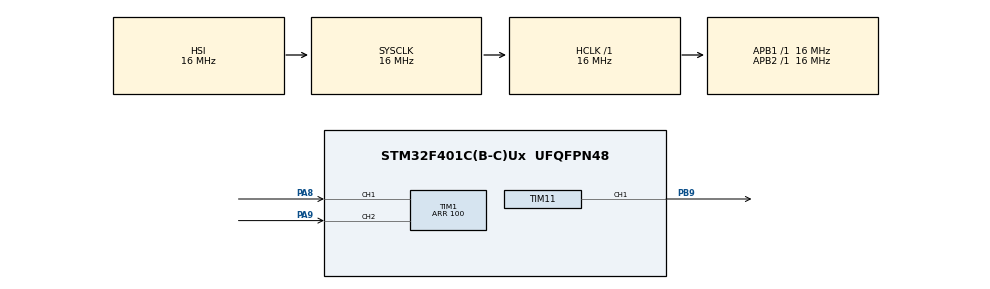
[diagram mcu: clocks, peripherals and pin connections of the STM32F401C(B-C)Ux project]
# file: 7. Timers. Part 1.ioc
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Mcu.Family=STM32F4
Mcu.Name=STM32F401C(B-C)Ux
Mcu.Package=UFQFPN48
NVIC.PriorityGroup=NVIC_PRIORITYGROUP_4
PA13.Mode=Serial_Wire
PA13.Signal=SYS_JTMS-SWDIO
PA14.Mode=Serial_Wire
PA14.Signal=SYS_JTCK-SWCLK
PA8.Signal=S_TIM1_CH1
PA9.Signal=S_TIM1_CH2
PB9.Signal=S_TIM11_CH1
ProjectManager.HeapSize=0x200
ProjectManager.StackSize=0x400
ProjectManager.TargetToolchain=STM32CubeIDE
RCC.AHBFreq_Value=16000000
RCC.APB1Freq_Value=16000000
RCC.APB2Freq_Value=16000000
RCC.CortexFreq_Value=16000000
RCC.HSE_VALUE=25000000
RCC.HSI_VALUE=16000000
RCC.LSE_VALUE=32768
RCC.SYSCLKFreq_VALUE=16000000
RCC.VCOOutputFreq_Value=192000000
SH.S_TIM11_CH1.0=TIM11_CH1,PWM Generation1 CH1
SH.S_TIM1_CH1.0=TIM1_CH1,Encoder_Interface
SH.S_TIM1_CH2.0=TIM1_CH2,Encoder_Interface
TIM1.EncoderMode=TIM_ENCODERMODE_TI12
TIM1.Period=100
TIM11.Channel=TIM_CHANNEL_1
TIM11.OCPolarity_1=TIM_OCPOLARITY_LOW
TIM11.Period=100-1
TIM11.Prescaler=16
VP_TIM11_VS_ClockSourceINT.Mode=Enable_Timer
board=custom

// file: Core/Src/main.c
/* USER CODE BEGIN Header */
/**
  ******************************************************************************
  * @file           : main.c
  * @brief          : Main program body
  ******************************************************************************
  * @attention
  *
  * Copyright (c) 2024 STMicroelectronics.
  * All rights reserved.
  *
  * This software is licensed under terms that can be found in the LICENSE file
  * in the root directory of this software component.
  * If no LICENSE file comes with this software, it is provided AS-IS.
  *
  ******************************************************************************
  */
/* USER CODE END Header */
#include "main.h"
#include "tim.h"
#include "gpio.h"

void SystemClock_Config(void);

int main(void)
{

  /* MCU Configuration--------------------------------------------------------*/

  /* Reset of all peripherals, Initializes the Flash interface and the Systick. */
  HAL_Init();

  /* Configure the system clock */
  SystemClock_Config();

  /* Initialize all configured peripherals */
  MX_GPIO_Init();
  MX_TIM1_Init();
  MX_TIM11_Init();

  /* Infinite loop */
  /* USER CODE BEGIN WHILE */

  TIM1_Encoder_Start();
  TIM11_PWM_Start();

  while (1)
  {
	TIM11->CCR1 = TIM1->CNT;
    /* USER CODE END WHILE */

    /* USER CODE BEGIN 3 */
  }

  return 0;
  /* USER CODE END 3 */
}

void SystemClock_Config(void)
{
  RCC_OscInitTypeDef RCC_OscInitStruct = {0};
  RCC_ClkInitTypeDef RCC_ClkInitStruct = {0};

  /** Configure the main internal regulator output voltage
  */
  __HAL_RCC_PWR_CLK_ENABLE();
  __HAL_PWR_VOLTAGESCALING_CONFIG(PWR_REGULATOR_VOLTAGE_SCALE2);

  /** Initializes the RCC Oscillators according to the specified parameters
  * in the RCC_OscInitTypeDef structure.
  */
  RCC_OscInitStruct.OscillatorType = RCC_OSCILLATORTYPE_HSI;
  RCC_OscInitStruct.HSIState = RCC_HSI_ON;
  RCC_OscInitStruct.HSICalibrationValue = RCC_HSICALIBRATION_DEFAULT;
  RCC_OscInitStruct.PLL.PLLState = RCC_PLL_NONE;
  if (HAL_RCC_OscConfig(&RCC_OscInitStruct) != HAL_OK)
  {
    Error_Handler();
  }

  /** Initializes the CPU, AHB and APB buses clocks
  */
  RCC_ClkInitStruct.ClockType = RCC_CLOCKTYPE_HCLK|RCC_CLOCKTYPE_SYSCLK
                              |RCC_CLOCKTYPE_PCLK1|RCC_CLOCKTYPE_PCLK2;
  RCC_ClkInitStruct.SYSCLKSource = RCC_SYSCLKSOURCE_HSI;
  RCC_ClkInitStruct.AHBCLKDivider = RCC_SYSCLK_DIV1;
  RCC_ClkInitStruct.APB1CLKDivider = RCC_HCLK_DIV1;
  RCC_ClkInitStruct.APB2CLKDivider = RCC_HCLK_DIV1;

  if (HAL_RCC_ClockConfig(&RCC_ClkInitStruct, FLASH_LATENCY_0) != HAL_OK)
  {
    Error_Handler();
  }
}

/* USER CODE BEGIN 4 */

void HAL_TIM_TriggerCallback(TIM_HandleTypeDef *htim)
{
	TIM11->CCR1 = TIM1->CNT;
}

/* USER CODE END 4 */

void Error_Handler(void)
{
  __disable_irq();
  while (1)
  {
  }
}
